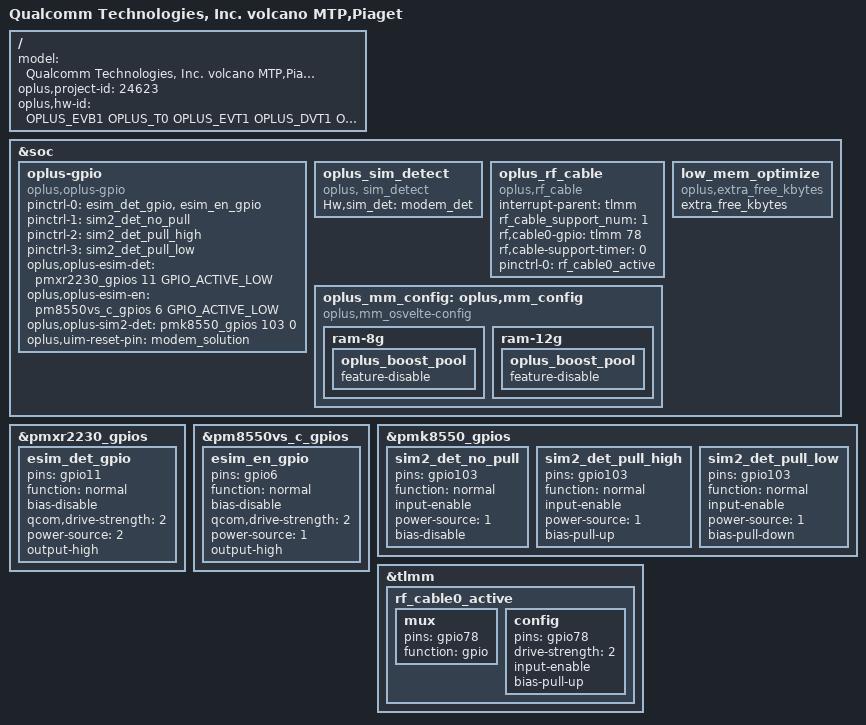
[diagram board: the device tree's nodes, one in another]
/dts-v1/;
/plugin/;
#include <dt-bindings/oplus/hw-id.h>
#include <dt-bindings/input/linux-event-codes.h>
#include "../qcom/volcano-mtp-overlay.dts"
#include "volcano_overlay_common.dtsi"
#include "piaget_overlay_common.dtsi"
#include "tp/piaget-oplus-tp-24623.dtsi"
#include "oplus_chg/oplus-chg-24623.dtsi"
#include "oplus_chg/pps/oplus-chg-piaget-pps.dtsi"
#include "sensor/piaget-sensor-24607.dtsi"
#include "oplus_fp/oplus_fp_24607.dtsi"
#include "oplus_misc/oplus-misc-24607_24697_24698.dtsi"

/ {
    model = "Qualcomm Technologies, Inc. volcano MTP,Piaget";

    oplus,project-id = <24623>;
    oplus,hw-id = <OPLUS_EVB1 OPLUS_T0 OPLUS_EVT1 OPLUS_DVT1 OPLUS_PVT1>;
};

&soc {
  //#ifdef OPLUS_FEATURE_ESIM
  oplus-gpio {
    compatible = "oplus,oplus-gpio";
    pinctrl-names = "oplus_esim", "sim2_det_no_pull", "sim2_det_pull_high", "sim2_det_pull_low";
    pinctrl-0 = <&esim_det_gpio &esim_en_gpio>;
    pinctrl-1 = <&sim2_det_no_pull>;
    pinctrl-2 = <&sim2_det_pull_high>;
    pinctrl-3 = <&sim2_det_pull_low>;
    oplus,oplus-esim-det = <&pmxr2230_gpios 11 GPIO_ACTIVE_LOW>;
    oplus,oplus-esim-en = <&pm8550vs_c_gpios 6 GPIO_ACTIVE_LOW>;
    oplus,oplus-sim2-det = <&pmk8550_gpios 103 0>;
    oplus,uim-reset-pin = "modem_solution";
  };
  oplus_sim_detect {
    compatible = "oplus, sim_detect";
    Hw,sim_det = "modem_det";
  };
  //#endif /*OPLUS_FEATURE_ESIM*/

  //#ifdef OPLUS_FEATURE_RF_CABLE_DETECT
  oplus_rf_cable {
      compatible = "oplus,rf_cable";
      interrupt-parent = <&tlmm>;
      rf_cable_support_num = <1>;
      rf,cable0-gpio = <&tlmm 78 0>;
      rf,cable-support-timer = <0>;
      pinctrl-names = "rf_cable_active";
      pinctrl-0 = <&rf_cable0_active>;
  };
  //#endif /* OPLUS_FEATURE_RF_CABLE_DETECT */
};


&pmxr2230_gpios {
  esim_det_gpio: esim_det_gpio {
      pins = "gpio11";
      function = "normal";
      bias-disable; /* NO pull */
      qcom,drive-strength = <2>; /* 2 MA */
      power-source = <2>; /* 1.2V */
      output-high;
  };
};

&pm8550vs_c_gpios {
  esim_en_gpio: esim_en_gpio {
      pins = "gpio6";
      function = "normal";
      bias-disable; /* NO pull */
      qcom,drive-strength = <2>; /* 2 MA */
      power-source = <1>; /* 1.8V */
      output-high;
  };
};

&pmk8550_gpios {
    sim2_det_no_pull: sim2_det_no_pull {
        pins = "gpio103";
        function = "normal";
        input-enable;
        power-source = <1>;
        bias-disable;
    };

    sim2_det_pull_high: sim2_det_pull_high {
        pins = "gpio103";
        function = "normal";
        input-enable;
        power-source = <1>;
        bias-pull-up;
    };

    sim2_det_pull_low: sim2_det_pull_low {
        pins = "gpio103";
        function = "normal";
        input-enable;
        power-source = <1>;
        bias-pull-down;
    };
};

&tlmm {
  //#ifdef OPLUS_FEATURE_RF_CABLE_DETECT
  rf_cable0_active: rf_cable0_active {
      mux {
          pins = "gpio78";
          function = "gpio";
      };
      config {
          pins = "gpio78";
          drive-strength = <2>;
          input-enable;
          bias-pull-up;
      };
  };
  //#endif /* OPLUS_FEATURE_RF_CABLE_DETECT */
};

&soc {
/* Add for low_mem_optimize */
    low_mem_optimize {
        compatible = "oplus,extra_free_kbytes";
        extra_free_kbytes;
    };
    oplus_mm_config: oplus,mm_config {
        compatible = "oplus,mm_osvelte-config";
    ram-8g{
        oplus_boost_pool {
            feature-disable;
        };
    };
    ram-12g {
        oplus_boost_pool {
            feature-disable;
        };
    };
    };
};
